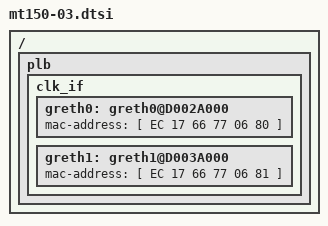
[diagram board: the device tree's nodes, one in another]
/*
 * Device Tree Source for RCM MT150.03 extention board (Ethernet)
 *
 * Copyright (C) 2020 MIR
 *	Mikhail.Petrov@mir.dev
 *
 * SPDX-License-Identifier: GPL-2.0+
 */
/ {
	plb {
		clk_if {
			greth0: greth0@D002A000 {
				status = "okay";
				mac-address = [ EC 17 66 77 06 80 ];
			};

			greth1: greth1@D003A000 {
				// status = "okay";
				mac-address = [ EC 17 66 77 06 81 ];
			};
		};
	};
};
